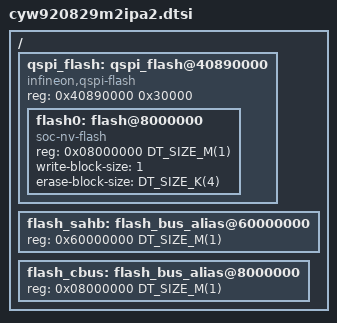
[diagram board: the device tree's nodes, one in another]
/*
 * Copyright (c) 2025 Infineon Technologies AG,
 * or an affiliate of Infineon Technologies AG.
 *
 * SPDX-License-Identifier: Apache-2.0
 */

/* SoM DTSI for CYW920829M2IPA2 processor card
 * Contains either CYW20829B0LKML or CYW20829B1010 silicon and an external QSPI
 */

/ {
	qspi_flash: qspi_flash@40890000 {
		compatible = "infineon,qspi-flash";
		reg = <0x40890000 0x30000>;
		#address-cells = <1>;
		#size-cells = <1>;
	};

	/* Flash aliased address path */
	flash_sahb: flash_bus_alias@60000000 {
		reg = <0x60000000 DT_SIZE_M(1)>;  /* SAHB address */
	};

	flash_cbus: flash_bus_alias@8000000 {
		reg = <0x08000000 DT_SIZE_M(1)>;  /* CBUS address */
	};
};

/* QSPI flash device on CYW920829M2IPA2 processor card */
&qspi_flash {
	flash0: flash@8000000 {
		compatible = "soc-nv-flash";
		reg = <0x08000000 DT_SIZE_M(1)>;
		write-block-size = <1>;
		erase-block-size = <DT_SIZE_K(4)>;
		#address-cells = <1>;
		#size-cells = <1>;
	};
};
